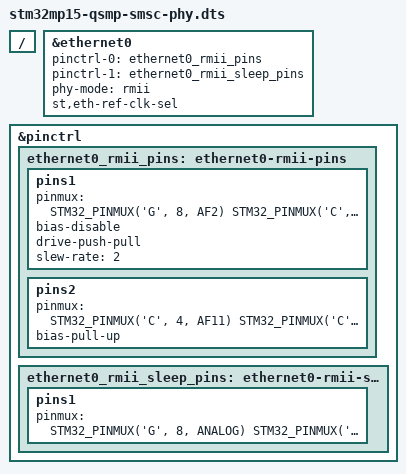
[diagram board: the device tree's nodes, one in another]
// SPDX-License-Identifier: (GPL-2.0 OR BSD-3-Clause)
/*
 * Copyright (C) 2022 Lothar Waßmann <LW@KARO-electronics.de>
 */

/dts-v1/;

/plugin/;

#include <dt-bindings/pinctrl/stm32-pinfunc.h>

/{
	#address-cells = <1>;
	#size-cells = <0>;

	fragment@0 {
		reg = <0>;
		target = <&ethernet0>;

		__overlay__ {
			pinctrl-0 = <&ethernet0_rmii_pins>;
			pinctrl-1 = <&ethernet0_rmii_sleep_pins>;
			phy-mode = "rmii";
			st,eth-ref-clk-sel;
		};
	};

	fragment@1 {
		reg = <1>;
		target = <&pinctrl>;

		__overlay__ {
			ethernet0_rmii_pins: ethernet0-rmii-pins {
				pins1 {
					pinmux = <
						  STM32_PINMUX('G', 8, AF2)	/* ETH_CLK */
						  STM32_PINMUX('C', 1, AF11)	/* ETH_MDC */
						  STM32_PINMUX('A', 2, AF11)	/* ETH_MDIO */
						  STM32_PINMUX('B', 11, AF11)	/* ETH_RMII_TX_EN */
						  STM32_PINMUX('G', 13, AF11)	/* ETH_RMII_TXD0 */
						  STM32_PINMUX('G', 14, AF11)	/* ETH_RMII_TXD1 */
					>;
					bias-disable;
					drive-push-pull;
					slew-rate = <2>;
				};

				pins2 {
					/* PHY configuration strap pins */
					pinmux = <
						  STM32_PINMUX('C', 4, AF11)	/* ETH_RMII_RXD0/MODE0 */
						  STM32_PINMUX('C', 5, AF11)	/* ETH_RMII_RXD1/MODE1 */
						  STM32_PINMUX('A', 7, AF11)	/* ETH_RMII_CRS_DV/MODE2 */
					>;
					bias-pull-up;
				};
			};

			ethernet0_rmii_sleep_pins: ethernet0-rmii-sleep-pins {
				pins1 {
					pinmux = <
						  STM32_PINMUX('G', 8, ANALOG)	/* ETH_CLK */
						  STM32_PINMUX('G', 13, ANALOG)	/* ETH_RMII_TXD0 */
						  STM32_PINMUX('G', 14, ANALOG)	/* ETH_RMII_TXD1 */
						  STM32_PINMUX('B', 11, ANALOG)	/* ETH_RMII_TX_EN */
						  STM32_PINMUX('A', 2, ANALOG)	/* ETH_MDIO */
						  STM32_PINMUX('C', 1, ANALOG)	/* ETH_MDC */
						  STM32_PINMUX('C', 4, ANALOG)	/* ETH_RMII_RXD0 */
						  STM32_PINMUX('C', 5, ANALOG)	/* ETH_RMII_RXD1 */
						  STM32_PINMUX('A', 7, ANALOG)	/* ETH_RMII_CRS_DV */
					>;
				};
			};
		};
	};
};
